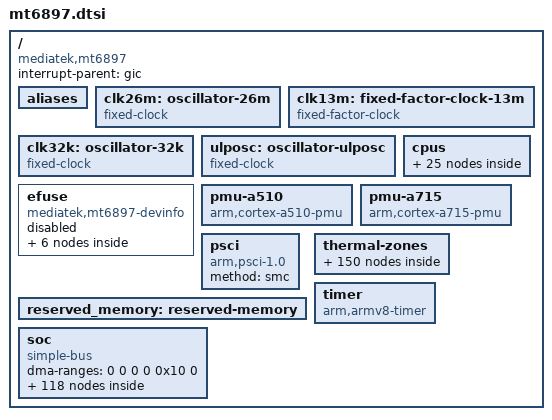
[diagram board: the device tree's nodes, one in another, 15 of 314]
// SPDX-License-Identifier: (GPL-2.0-only OR BSD-2-Clause)
/*
 * MediaTek MT6897 (Dimensity 8300, sold as MT8792 in tablets) SoC
 *
 * Copyright (c) 2026 buntOS contributors
 *
 * Register and interrupt values come from the SoC device tree in the
 * Lenovo TB373FU/TB375FC stock firmware and were checked against the
 * MediaTek downstream mt6897.dts and the community port
 * https://github.com/u0n0u/tb375fc-linux. Blocks that need the missing
 * clock, pinctrl and power domain drivers are described but disabled.
 */

#include <dt-bindings/thermal/thermal.h>
#include <dt-bindings/clock/mediatek,mt6897-clock.h>
#include <dt-bindings/interrupt-controller/arm-gic.h>
#include <dt-bindings/interrupt-controller/irq.h>
#include <dt-bindings/memory/mediatek,mt6897-memory-port.h>
#include <dt-bindings/phy/phy.h>
#include <dt-bindings/power/mediatek,mt6897-power.h>
#include <dt-bindings/reset/mediatek,mt6897-resets.h>
#include <dt-bindings/thermal/mediatek,lvts-thermal.h>

/ {
	compatible = "mediatek,mt6897";
	interrupt-parent = <&gic>;
	#address-cells = <2>;
	#size-cells = <2>;

	/*
	 * mediatek-drm finds the blocks of the display by these. The numbers of
	 * the display controllers are in mt6897_main_controllers of mtk_drm_drv.c.
	 */
	aliases {
		dsc0 = &dsc0;
		dsc1 = &dsc1;
		dsi0 = &dsi0;
		dsi1 = &dsi1;
		mmsys0 = &dispsys0;
		mmsys1 = &dispsys1;
		mmsys2 = &ovlsys0;
		mmsys3 = &ovlsys1;
		mutex0 = &disp_mutex0;
		mutex1 = &disp_mutex1;
		mutex2 = &ovl_mutex0;
		mutex3 = &ovl_mutex1;
		ovl-2l0 = &ovl_2l0;
		ovl-2l1 = &ovl_2l1;
	};

	clk26m: oscillator-26m {
		compatible = "fixed-clock";
		#clock-cells = <0>;
		clock-frequency = <26000000>;
		clock-output-names = "clk26m";
	};

	clk13m: fixed-factor-clock-13m {
		compatible = "fixed-factor-clock";
		#clock-cells = <0>;
		clocks = <&clk26m>;
		clock-div = <2>;
		clock-mult = <1>;
		clock-output-names = "clk13m";
	};

	/* The stock firmware gives 32000 Hz, not 32768 */
	clk32k: oscillator-32k {
		compatible = "fixed-clock";
		#clock-cells = <0>;
		clock-frequency = <32000>;
		clock-output-names = "clk32k";
	};

	/* On-chip ultra low power oscillator, the osc_dN dividers' parent */
	ulposc: oscillator-ulposc {
		compatible = "fixed-clock";
		#clock-cells = <0>;
		clock-frequency = <588000000>;
		clock-output-names = "ulposc";
	};

	cpus {
		#address-cells = <1>;
		#size-cells = <0>;

		cpu0: cpu@0 {
			device_type = "cpu";
			compatible = "arm,cortex-a510";
			reg = <0x000>;
			enable-method = "psci";
			performance-domains = <&performance 0>;
			capacity-dmips-mhz = <338>;
			#cooling-cells = <2>;
			cpu-idle-states = <&cpu_off_l &cluster_off_l>;
		};

		cpu1: cpu@100 {
			device_type = "cpu";
			compatible = "arm,cortex-a510";
			reg = <0x100>;
			enable-method = "psci";
			performance-domains = <&performance 0>;
			capacity-dmips-mhz = <338>;
			#cooling-cells = <2>;
			cpu-idle-states = <&cpu_off_l &cluster_off_l>;
		};

		cpu2: cpu@200 {
			device_type = "cpu";
			compatible = "arm,cortex-a510";
			reg = <0x200>;
			enable-method = "psci";
			performance-domains = <&performance 0>;
			capacity-dmips-mhz = <338>;
			#cooling-cells = <2>;
			cpu-idle-states = <&cpu_off_l &cluster_off_l>;
		};

		cpu3: cpu@300 {
			device_type = "cpu";
			compatible = "arm,cortex-a510";
			reg = <0x300>;
			enable-method = "psci";
			performance-domains = <&performance 0>;
			capacity-dmips-mhz = <338>;
			#cooling-cells = <2>;
			cpu-idle-states = <&cpu_off_l &cluster_off_l>;
		};

		cpu4: cpu@400 {
			device_type = "cpu";
			compatible = "arm,cortex-a715";
			reg = <0x400>;
			enable-method = "psci";
			performance-domains = <&performance 1>;
			capacity-dmips-mhz = <1080>;
			#cooling-cells = <2>;
			cpu-idle-states = <&cpu_off_m &cluster_off_m>;
		};

		cpu5: cpu@500 {
			device_type = "cpu";
			compatible = "arm,cortex-a715";
			reg = <0x500>;
			enable-method = "psci";
			performance-domains = <&performance 1>;
			capacity-dmips-mhz = <1080>;
			#cooling-cells = <2>;
			cpu-idle-states = <&cpu_off_m &cluster_off_m>;
		};

		cpu6: cpu@600 {
			device_type = "cpu";
			compatible = "arm,cortex-a715";
			reg = <0x600>;
			enable-method = "psci";
			performance-domains = <&performance 1>;
			capacity-dmips-mhz = <1080>;
			#cooling-cells = <2>;
			cpu-idle-states = <&cpu_off_m &cluster_off_m>;
		};

		cpu7: cpu@700 {
			device_type = "cpu";
			compatible = "arm,cortex-a715";
			reg = <0x700>;
			enable-method = "psci";
			performance-domains = <&performance 2>;
			capacity-dmips-mhz = <1024>;
			#cooling-cells = <2>;
			cpu-idle-states = <&cpu_off_b &cluster_off_b>;
		};

		/* One DynamIQ cluster; the three DVFS domains are performance-domains */
		cpu-map {
			cluster0 {
				core0 {
					cpu = <&cpu0>;
				};

				core1 {
					cpu = <&cpu1>;
				};

				core2 {
					cpu = <&cpu2>;
				};

				core3 {
					cpu = <&cpu3>;
				};

				core4 {
					cpu = <&cpu4>;
				};

				core5 {
					cpu = <&cpu5>;
				};

				core6 {
					cpu = <&cpu6>;
				};

				core7 {
					cpu = <&cpu7>;
				};
			};
		};

		/*
		 * Only the CPU and cluster power-down states. The deeper MCUSYS
		 * and system states are coordinated by the SPM and need its
		 * driver first.
		 */
		idle-states {
			entry-method = "psci";

			cpu_off_l: cpu-off-l {
				compatible = "arm,idle-state";
				arm,psci-suspend-param = <0x00010000>;
				local-timer-stop;
				entry-latency-us = <126>;
				exit-latency-us = <251>;
				min-residency-us = <5700>;
			};

			cpu_off_m: cpu-off-m {
				compatible = "arm,idle-state";
				arm,psci-suspend-param = <0x00010000>;
				local-timer-stop;
				entry-latency-us = <77>;
				exit-latency-us = <179>;
				min-residency-us = <2520>;
			};

			cpu_off_b: cpu-off-b {
				compatible = "arm,idle-state";
				arm,psci-suspend-param = <0x00010000>;
				local-timer-stop;
				entry-latency-us = <52>;
				exit-latency-us = <129>;
				min-residency-us = <1890>;
			};

			cluster_off_l: cluster-off-l {
				compatible = "arm,idle-state";
				arm,psci-suspend-param = <0x01010001>;
				local-timer-stop;
				entry-latency-us = <143>;
				exit-latency-us = <420>;
				min-residency-us = <5700>;
			};

			cluster_off_m: cluster-off-m {
				compatible = "arm,idle-state";
				arm,psci-suspend-param = <0x01010001>;
				local-timer-stop;
				entry-latency-us = <82>;
				exit-latency-us = <253>;
				min-residency-us = <3020>;
			};

			cluster_off_b: cluster-off-b {
				compatible = "arm,idle-state";
				arm,psci-suspend-param = <0x01010001>;
				local-timer-stop;
				entry-latency-us = <46>;
				exit-latency-us = <150>;
				min-residency-us = <2460>;
			};
		};
	};

	/*
	 * The fuses as the boot firmware passes them on. The cell offsets are in
	 * that copy (atag,devinfo), not in the efuse block at 0x11e80000.
	 */
	efuse: efuse {
		compatible = "mediatek,mt6897-devinfo";
		status = "disabled";

		nvmem-layout {
			compatible = "fixed-layout";
			#address-cells = <1>;
			#size-cells = <1>;

			/* Termination trims of CSI port 0, for the seninf */
			csi_trim0: csi-trim@1d4 {
				reg = <0x1d4 0x4>;
			};

			lvts_calib2: calib@2d4 {
				reg = <0x2d4 0x28>;
			};

			lvts_calib4: calib@2fc {
				reg = <0x2fc 0x10>;
			};

			lvts_calib1: calib@310 {
				reg = <0x310 0x38>;
			};

			lvts_calib3: calib@364 {
				reg = <0x364 0x4>;
			};
		};
	};

	pmu-a510 {
		compatible = "arm,cortex-a510-pmu";
		interrupt-parent = <&gic>;
		interrupts = <GIC_PPI 7 IRQ_TYPE_LEVEL_HIGH &ppi_cluster0>;
	};

	pmu-a715 {
		compatible = "arm,cortex-a715-pmu";
		interrupt-parent = <&gic>;
		interrupts = <GIC_PPI 7 IRQ_TYPE_LEVEL_HIGH &ppi_cluster1>;
	};

	psci {
		compatible = "arm,psci-1.0";
		method = "smc";
	};

	/*
	 * The bootloader adds its fixed carve-outs (ATF, TEE, GenieZone,
	 * connsys, framebuffer, ...) here at boot.
	 */
	reserved_memory: reserved-memory {
		#address-cells = <2>;
		#size-cells = <2>;
		ranges;
	};

	thermal-zones {
		cpu4-0-thermal {
			polling-delay = <1000>;
			polling-delay-passive = <150>;
			thermal-sensors = <&lvts_mcu MT6897_MCU_MEDIUM_CPU4_0>;

			trips {
				cpu4_0_alert: trip-alert {
					temperature = <85000>;
					hysteresis = <2000>;
					type = "passive";
				};

				trip-crit {
					temperature = <115000>;
					hysteresis = <2000>;
					type = "critical";
				};
			};

			cooling-maps {
				map0 {
					trip = <&cpu4_0_alert>;
					cooling-device = <&cpu4 THERMAL_NO_LIMIT THERMAL_NO_LIMIT>;
				};
			};
		};

		cpu4-1-thermal {
			polling-delay = <1000>;
			polling-delay-passive = <150>;
			thermal-sensors = <&lvts_mcu MT6897_MCU_MEDIUM_CPU4_1>;

			trips {
				cpu4_1_alert: trip-alert {
					temperature = <85000>;
					hysteresis = <2000>;
					type = "passive";
				};

				trip-crit {
					temperature = <115000>;
					hysteresis = <2000>;
					type = "critical";
				};
			};

			cooling-maps {
				map0 {
					trip = <&cpu4_1_alert>;
					cooling-device = <&cpu4 THERMAL_NO_LIMIT THERMAL_NO_LIMIT>;
				};
			};
		};

		cpu5-0-thermal {
			polling-delay = <1000>;
			polling-delay-passive = <150>;
			thermal-sensors = <&lvts_mcu MT6897_MCU_MEDIUM_CPU5_0>;

			trips {
				cpu5_0_alert: trip-alert {
					temperature = <85000>;
					hysteresis = <2000>;
					type = "passive";
				};

				trip-crit {
					temperature = <115000>;
					hysteresis = <2000>;
					type = "critical";
				};
			};

			cooling-maps {
				map0 {
					trip = <&cpu5_0_alert>;
					cooling-device = <&cpu4 THERMAL_NO_LIMIT THERMAL_NO_LIMIT>;
				};
			};
		};

		cpu5-1-thermal {
			polling-delay = <1000>;
			polling-delay-passive = <150>;
			thermal-sensors = <&lvts_mcu MT6897_MCU_MEDIUM_CPU5_1>;

			trips {
				cpu5_1_alert: trip-alert {
					temperature = <85000>;
					hysteresis = <2000>;
					type = "passive";
				};

				trip-crit {
					temperature = <115000>;
					hysteresis = <2000>;
					type = "critical";
				};
			};

			cooling-maps {
				map0 {
					trip = <&cpu5_1_alert>;
					cooling-device = <&cpu4 THERMAL_NO_LIMIT THERMAL_NO_LIMIT>;
				};
			};
		};

		cpu2-thermal {
			polling-delay = <1000>;
			polling-delay-passive = <150>;
			thermal-sensors = <&lvts_mcu MT6897_MCU_LITTLE_CPU2>;

			trips {
				cpu2_alert: trip-alert {
					temperature = <85000>;
					hysteresis = <2000>;
					type = "passive";
				};

				trip-crit {
					temperature = <115000>;
					hysteresis = <2000>;
					type = "critical";
				};
			};

			cooling-maps {
				map0 {
					trip = <&cpu2_alert>;
					cooling-device = <&cpu0 THERMAL_NO_LIMIT THERMAL_NO_LIMIT>;
				};
			};
		};

		cpu3-thermal {
			polling-delay = <1000>;
			polling-delay-passive = <150>;
			thermal-sensors = <&lvts_mcu MT6897_MCU_LITTLE_CPU3>;

			trips {
				cpu3_alert: trip-alert {
					temperature = <85000>;
					hysteresis = <2000>;
					type = "passive";
				};

				trip-crit {
					temperature = <115000>;
					hysteresis = <2000>;
					type = "critical";
				};
			};

			cooling-maps {
				map0 {
					trip = <&cpu3_alert>;
					cooling-device = <&cpu0 THERMAL_NO_LIMIT THERMAL_NO_LIMIT>;
				};
			};
		};

		cpu6-0-thermal {
			polling-delay = <1000>;
			polling-delay-passive = <150>;
			thermal-sensors = <&lvts_mcu MT6897_MCU_MEDIUM_CPU6_0>;

			trips {
				cpu6_0_alert: trip-alert {
					temperature = <85000>;
					hysteresis = <2000>;
					type = "passive";
				};

				trip-crit {
					temperature = <115000>;
					hysteresis = <2000>;
					type = "critical";
				};
			};

			cooling-maps {
				map0 {
					trip = <&cpu6_0_alert>;
					cooling-device = <&cpu4 THERMAL_NO_LIMIT THERMAL_NO_LIMIT>;
				};
			};
		};

		cpu6-1-thermal {
			polling-delay = <1000>;
			polling-delay-passive = <150>;
			thermal-sensors = <&lvts_mcu MT6897_MCU_MEDIUM_CPU6_1>;

			trips {
				cpu6_1_alert: trip-alert {
					temperature = <85000>;
					hysteresis = <2000>;
					type = "passive";
				};

				trip-crit {
					temperature = <115000>;
					hysteresis = <2000>;
					type = "critical";
				};
			};

			cooling-maps {
				map0 {
					trip = <&cpu6_1_alert>;
					cooling-device = <&cpu4 THERMAL_NO_LIMIT THERMAL_NO_LIMIT>;
				};
			};
		};

		dsu0-thermal {
			polling-delay = <1000>;
			polling-delay-passive = <150>;
			thermal-sensors = <&lvts_mcu MT6897_MCU_DSU0>;

			trips {
				dsu0_alert: trip-alert {
					temperature = <85000>;
					hysteresis = <2000>;
					type = "passive";
				};

				trip-crit {
					temperature = <115000>;
					hysteresis = <2000>;
					type = "critical";
				};
			};

			cooling-maps {
				map0 {
					trip = <&dsu0_alert>;
					cooling-device = <&cpu0 THERMAL_NO_LIMIT THERMAL_NO_LIMIT>,
							 <&cpu4 THERMAL_NO_LIMIT THERMAL_NO_LIMIT>,
							 <&cpu7 THERMAL_NO_LIMIT THERMAL_NO_LIMIT>;
				};
			};
		};

		cpu0-thermal {
			polling-delay = <1000>;
			polling-delay-passive = <150>;
			thermal-sensors = <&lvts_mcu MT6897_MCU_LITTLE_CPU0>;

			trips {
				cpu0_alert: trip-alert {
					temperature = <85000>;
					hysteresis = <2000>;
					type = "passive";
				};

				trip-crit {
					temperature = <115000>;
					hysteresis = <2000>;
					type = "critical";
				};
			};

			cooling-maps {
				map0 {
					trip = <&cpu0_alert>;
					cooling-device = <&cpu0 THERMAL_NO_LIMIT THERMAL_NO_LIMIT>;
				};
			};
		};

		cpu1-thermal {
			polling-delay = <1000>;
			polling-delay-passive = <150>;
			thermal-sensors = <&lvts_mcu MT6897_MCU_LITTLE_CPU1>;

			trips {
				cpu1_alert: trip-alert {
					temperature = <85000>;
					hysteresis = <2000>;
					type = "passive";
				};

				trip-crit {
					temperature = <115000>;
					hysteresis = <2000>;
					type = "critical";
				};
			};

			cooling-maps {
				map0 {
					trip = <&cpu1_alert>;
					cooling-device = <&cpu0 THERMAL_NO_LIMIT THERMAL_NO_LIMIT>;
				};
			};
		};

		dsu1-thermal {
			polling-delay = <1000>;
			polling-delay-passive = <150>;
			thermal-sensors = <&lvts_mcu MT6897_MCU_DSU1>;

			trips {
				dsu1_alert: trip-alert {
					temperature = <85000>;
					hysteresis = <2000>;
					type = "passive";
				};

				trip-crit {
					temperature = <115000>;
					hysteresis = <2000>;
					type = "critical";
				};
			};

			cooling-maps {
				map0 {
					trip = <&dsu1_alert>;
					cooling-device = <&cpu0 THERMAL_NO_LIMIT THERMAL_NO_LIMIT>,
							 <&cpu4 THERMAL_NO_LIMIT THERMAL_NO_LIMIT>,
							 <&cpu7 THERMAL_NO_LIMIT THERMAL_NO_LIMIT>;
				};
			};
		};

		cpu7-0-thermal {
			polling-delay = <1000>;
			polling-delay-passive = <150>;
			thermal-sensors = <&lvts_mcu MT6897_MCU_BIG_CPU7_0>;

			trips {
				cpu7_0_alert: trip-alert {
					temperature = <85000>;
					hysteresis = <2000>;
					type = "passive";
				};

				trip-crit {
					temperature = <115000>;
					hysteresis = <2000>;
					type = "critical";
				};
			};

			cooling-maps {
				map0 {
					trip = <&cpu7_0_alert>;
					cooling-device = <&cpu7 THERMAL_NO_LIMIT THERMAL_NO_LIMIT>;
				};
			};
		};

		cpu7-1-thermal {
			polling-delay = <1000>;
			polling-delay-passive = <150>;
			thermal-sensors = <&lvts_mcu MT6897_MCU_BIG_CPU7_1>;

			trips {
				cpu7_1_alert: trip-alert {
					temperature = <85000>;
					hysteresis = <2000>;
					type = "passive";
				};

				trip-crit {
					temperature = <115000>;
					hysteresis = <2000>;
					type = "critical";
				};
			};

			cooling-maps {
				map0 {
					trip = <&cpu7_1_alert>;
					cooling-device = <&cpu7 THERMAL_NO_LIMIT THERMAL_NO_LIMIT>;
				};
			};
		};

		dsu2-thermal {
			polling-delay = <1000>;
			polling-delay-passive = <150>;
			thermal-sensors = <&lvts_mcu MT6897_MCU_DSU2>;

			trips {
				dsu2_alert: trip-alert {
					temperature = <85000>;
					hysteresis = <2000>;
					type = "passive";
				};

				trip-crit {
					temperature = <115000>;
					hysteresis = <2000>;
					type = "critical";
				};
			};

			cooling-maps {
				map0 {
					trip = <&dsu2_alert>;
					cooling-device = <&cpu0 THERMAL_NO_LIMIT THERMAL_NO_LIMIT>,
							 <&cpu4 THERMAL_NO_LIMIT THERMAL_NO_LIMIT>,
							 <&cpu7 THERMAL_NO_LIMIT THERMAL_NO_LIMIT>;
				};
			};
		};

		dsu3-thermal {
			polling-delay = <1000>;
			polling-delay-passive = <150>;
			thermal-sensors = <&lvts_mcu MT6897_MCU_DSU3>;

			trips {
				dsu3_alert: trip-alert {
					temperature = <85000>;
					hysteresis = <2000>;
					type = "passive";
				};

				trip-crit {
					temperature = <115000>;
					hysteresis = <2000>;
					type = "critical";
				};
			};

			cooling-maps {
				map0 {
					trip = <&dsu3_alert>;
					cooling-device = <&cpu0 THERMAL_NO_LIMIT THERMAL_NO_LIMIT>,
							 <&cpu4 THERMAL_NO_LIMIT THERMAL_NO_LIMIT>,
							 <&cpu7 THERMAL_NO_LIMIT THERMAL_NO_LIMIT>;
				};
			};
		};

		soc-top0-thermal {
			polling-delay = <1000>;
			thermal-sensors = <&lvts_ap MT6897_AP_TOP0>;

			trips {
				trip-crit {
					temperature = <115000>;
					hysteresis = <2000>;
					type = "critical";
				};
			};
		};

		soc-top1-thermal {
			polling-delay = <1000>;
			thermal-sensors = <&lvts_ap MT6897_AP_TOP1>;

			trips {
				trip-crit {
					temperature = <115000>;
					hysteresis = <2000>;
					type = "critical";
				};
			};
		};

		soc-top2-thermal {
			polling-delay = <1000>;
			thermal-sensors = <&lvts_ap MT6897_AP_TOP2>;

			trips {
				trip-crit {
					temperature = <115000>;
					hysteresis = <2000>;
					type = "critical";
				};
			};
		};

		soc-top3-thermal {
			polling-delay = <1000>;
			thermal-sensors = <&lvts_ap MT6897_AP_TOP3>;

			trips {
				trip-crit {
					temperature = <115000>;
					hysteresis = <2000>;
					type = "critical";
				};
			};
		};

		soc-bot0-thermal {
			polling-delay = <1000>;
			thermal-sensors = <&lvts_ap MT6897_AP_BOT0>;

			trips {
				trip-crit {
					temperature = <115000>;
					hysteresis = <2000>;
					type = "critical";
				};
			};
		};

		soc-bot1-thermal {
			polling-delay = <1000>;
			thermal-sensors = <&lvts_ap MT6897_AP_BOT1>;

			trips {
				trip-crit {
					temperature = <115000>;
					hysteresis = <2000>;
					type = "critical";
				};
			};
		};

		soc-bot2-thermal {
			polling-delay = <1000>;
			thermal-sensors = <&lvts_ap MT6897_AP_BOT2>;

			trips {
				trip-crit {
					temperature = <115000>;
					hysteresis = <2000>;
					type = "critical";
				};
			};
		};

		soc-bot3-thermal {
			polling-delay = <1000>;
			thermal-sensors = <&lvts_ap MT6897_AP_BOT3>;

			trips {
				trip-crit {
					temperature = <115000>;
					hysteresis = <2000>;
					type = "critical";
				};
			};
		};

		md0-thermal {
			polling-delay = <1000>;
			thermal-sensors = <&lvts_ap MT6897_AP_MD0>;

			trips {
				trip-crit {
					temperature = <115000>;
					hysteresis = <2000>;
					type = "critical";
				};
			};
		};

		md1-thermal {
			polling-delay = <1000>;
			thermal-sensors = <&lvts_ap MT6897_AP_MD1>;

			trips {
				trip-crit {
					temperature = <115000>;
					hysteresis = <2000>;
					type = "critical";
				};
			};
		};

		md2-thermal {
			polling-delay = <1000>;
			thermal-sensors = <&lvts_ap MT6897_AP_MD2>;

			trips {
				trip-crit {
					temperature = <115000>;
					hysteresis = <2000>;
					type = "critical";
				};
			};
		};

		md3-thermal {
			polling-delay = <1000>;
			thermal-sensors = <&lvts_ap MT6897_AP_MD3>;

			trips {
				trip-crit {
					temperature = <115000>;
					hysteresis = <2000>;
					type = "critical";
				};
			};
		};

		apu0-thermal {
			polling-delay = <1000>;
			thermal-sensors = <&lvts_apu MT6897_APU0>;

			trips {
				trip-crit {
					temperature = <115000>;
					hysteresis = <2000>;
					type = "critical";
				};
			};
		};

		apu1-thermal {
			polling-delay = <1000>;
			thermal-sensors = <&lvts_apu MT6897_APU1>;

			trips {
				trip-crit {
					temperature = <115000>;
					hysteresis = <2000>;
					type = "critical";
				};
			};
		};

		gpu0-thermal {
			polling-delay = <1000>;
			polling-delay-passive = <150>;
			thermal-sensors = <&lvts_gpu MT6897_GPU0>;

			trips {
				gpu0_alert: trip-alert {
					temperature = <85000>;
					hysteresis = <2000>;
					type = "passive";
				};

				trip-crit {
					temperature = <115000>;
					hysteresis = <2000>;
					type = "critical";
				};
			};

			cooling-maps {
				map0 {
					trip = <&gpu0_alert>;
					cooling-device = <&gpu THERMAL_NO_LIMIT THERMAL_NO_LIMIT>;
				};
			};
		};

		gpu1-thermal {
			polling-delay = <1000>;
			polling-delay-passive = <150>;
			thermal-sensors = <&lvts_gpu MT6897_GPU1>;

			trips {
				gpu1_alert: trip-alert {
					temperature = <85000>;
					hysteresis = <2000>;
					type = "passive";
				};

				trip-crit {
					temperature = <115000>;
					hysteresis = <2000>;
					type = "critical";
				};
			};

			cooling-maps {
				map0 {
					trip = <&gpu1_alert>;
					cooling-device = <&gpu THERMAL_NO_LIMIT THERMAL_NO_LIMIT>;
				};
			};
		};
	};

	timer: timer {
		compatible = "arm,armv8-timer";
		interrupt-parent = <&gic>;
		interrupts = <GIC_PPI 13 IRQ_TYPE_LEVEL_HIGH 0>,
			     <GIC_PPI 14 IRQ_TYPE_LEVEL_HIGH 0>,
			     <GIC_PPI 11 IRQ_TYPE_LEVEL_HIGH 0>,
			     <GIC_PPI 10 IRQ_TYPE_LEVEL_HIGH 0>;
		clock-frequency = <13000000>;
	};

	soc {
		compatible = "simple-bus";
		#address-cells = <2>;
		#size-cells = <2>;
		ranges;
		dma-ranges = <0 0 0 0 0x10 0>;

		/* CPU DVFS in the MCUPM, one register bank per frequency domain */
		performance: performance-controller@11bc10 {
			compatible = "mediatek,cpufreq-hw";
			reg = <0 0x0011bc10 0 0x120>,
			      <0 0x0011bd30 0 0x120>,
			      <0 0x0011be50 0 0x120>;
			#performance-domain-cells = <1>;
		};

		/* Needed before the firmware accepts PSCI CPU_SUSPEND */
		mcupm@c0bf600 {
			compatible = "mediatek,mt6897-mcupm";
			reg = <0 0x0c0bf600 0 0xa00>;
		};

		/*
		 * Unlike MT8183..MT8195 the GIC is not at 0x0c000000: that
		 * range is MCUSYS (mcucfg, CPU PLLs, MCUPM at 0x0c070000).
		 * Both the shipped SoC tree and the tree the bootloader hands
		 * to the kernel use this base, as does the community port.
		 */
		gic: interrupt-controller@c400000 {
			compatible = "arm,gic-v3";
			#interrupt-cells = <4>;
			#redistributor-regions = <1>;
			interrupt-parent = <&gic>;
			interrupt-controller;
			reg = <0 0x0c400000 0 0x40000>,
			      <0 0x0c440000 0 0x200000>;
			interrupts = <GIC_PPI 9 IRQ_TYPE_LEVEL_HIGH 0>;

			ppi-partitions {
				ppi_cluster0: interrupt-partition-0 {
					affinity = <&cpu0 &cpu1 &cpu2 &cpu3>;
				};

				ppi_cluster1: interrupt-partition-1 {
					affinity = <&cpu4 &cpu5 &cpu6 &cpu7>;
				};
			};
		};

		/*
		 * The clock controllers stay off in 2a, which runs on the clocks
		 * the bootloader left on. TODO(2b): enable all six together with
		 * pio and SPMI, keeping clk_ignore_unused on the command line.
		 */
		topckgen: clock-controller@10000000 {
			compatible = "mediatek,mt6897-topckgen", "syscon";
			reg = <0 0x10000000 0 0x1000>;
			mediatek,hardware-voter = <&hwv>;
			#clock-cells = <1>;
			status = "disabled";
		};

		/*
		 * 232 GPIOs and the five EINT blocks. EINTs 232-249 have no
		 * pin; the driver gives them virtual GPIOs (the SPMI rcs
		 * interrupt is EINT 248). TODO(2b): enable together with SPMI.
		 */
		pio: pinctrl@10005000 {
			compatible = "mediatek,mt6897-pinctrl";
			reg = <0 0x10005000 0 0x1000>,
			      <0 0x11b20000 0 0x1000>,
			      <0 0x11c00000 0 0x1000>,
			      <0 0x11d30000 0 0x1000>,
			      <0 0x11d40000 0 0x1000>,
			      <0 0x11d50000 0 0x1000>,
			      <0 0x11ea0000 0 0x1000>,
			      <0 0x11eb0000 0 0x1000>,
			      <0 0x11f20000 0 0x1000>,
			      <0 0x11f30000 0 0x1000>,
			      <0 0x11ce0000 0 0x1000>,
			      <0 0x11de0000 0 0x1000>,
			      <0 0x11e90000 0 0x1000>,
			      <0 0x11fe0000 0 0x1000>,
			      <0 0x1c01e000 0 0x1000>;
			reg-names = "base", "rt", "rm", "bl", "bm", "br",
				    "lb", "lt", "tm", "tl", "eint-e", "eint-s",
				    "eint-w", "eint-n", "eint-c";
			gpio-controller;
			#gpio-cells = <2>;
			gpio-ranges = <&pio 0 0 232>;
			interrupt-controller;
			interrupts = <GIC_SPI 309 IRQ_TYPE_LEVEL_HIGH 0>;
			#interrupt-cells = <2>;
			status = "disabled";
		};

		apmixedsys: clock-controller@1000c000 {
			compatible = "mediatek,mt6897-apmixedsys", "syscon";
			reg = <0 0x1000c000 0 0x1000>;
			mediatek,hardware-voter = <&hwv>;
			#clock-cells = <1>;
			status = "disabled";
		};

		/*
		 * Bus protection registers of the power domains, which take them
		 * as a regmap. They stay disabled: nothing binds to a plain
		 * syscon, and fw_devlink would make the power controller wait
		 * for it through access-controllers until the deferred probe
		 * timeout.
		 */
		ifr_bus: syscon@1002c000 {
			compatible = "mediatek,mt6897-ifr-bus", "syscon";
			reg = <0 0x1002c000 0 0x1000>;
			status = "disabled";
		};

		/*
		 * Hardware voter: collects the clock votes of the AP and the
		 * remote processors, and switches some PLLs, muxes and gates,
		 * and some of the power domains.
		 */
		lvts_ap: thermal-sensor@10315000 {
			compatible = "mediatek,mt6897-lvts-ap";
			reg = <0 0x10315000 0 0x1000>;
			interrupts = <GIC_SPI 264 IRQ_TYPE_LEVEL_HIGH 0>;
			nvmem-cells = <&lvts_calib1>, <&lvts_calib2>,
				      <&lvts_calib3>, <&lvts_calib4>;
			nvmem-cell-names = "lvts-calib-data-1", "lvts-calib-data-2",
					   "lvts-calib-data-3", "lvts-calib-data-4";
			#thermal-sensor-cells = <1>;
			status = "disabled";
		};

		lvts_mcu: thermal-sensor@10316000 {
			compatible = "mediatek,mt6897-lvts-mcu";
			reg = <0 0x10316000 0 0x1000>;
			interrupts = <GIC_SPI 265 IRQ_TYPE_LEVEL_HIGH 0>;
			nvmem-cells = <&lvts_calib1>, <&lvts_calib2>,
				      <&lvts_calib3>, <&lvts_calib4>;
			nvmem-cell-names = "lvts-calib-data-1", "lvts-calib-data-2",
					   "lvts-calib-data-3", "lvts-calib-data-4";
			#thermal-sensor-cells = <1>;
			status = "disabled";
		};

		hwv: syscon@10320000 {
			compatible = "mediatek,mt6897-hwv", "syscon";
			reg = <0 0x10320000 0 0x2000>;
		};

		/*
		 * 8250_mtk needs a "bus" clock next to "baud". uart0 is the 2a
		 * console, so it keeps clk26m there and does not wait for the
		 * clock controllers. TODO(2b): <&pericfg_ao CLK_PERI_AO_UART0>.
		 */
		uart0: serial@11001000 {
			compatible = "mediatek,mt6897-uart", "mediatek,mt6577-uart";
			reg = <0 0x11001000 0 0x1000>;
			interrupts = <GIC_SPI 250 IRQ_TYPE_LEVEL_HIGH 0>;
			clocks = <&clk26m>, <&clk26m>;
			clock-names = "baud", "bus";
			status = "disabled";
		};

		uart1: serial@11002000 {
			compatible = "mediatek,mt6897-uart", "mediatek,mt6577-uart";
			reg = <0 0x11002000 0 0x1000>;
			interrupts = <GIC_SPI 251 IRQ_TYPE_LEVEL_HIGH 0>;
			clocks = <&clk26m>, <&pericfg_ao CLK_PERI_AO_UART1>;
			clock-names = "baud", "bus";
			status = "disabled";
		};

		uart2: serial@11003000 {
			compatible = "mediatek,mt6897-uart", "mediatek,mt6577-uart";
			reg = <0 0x11003000 0 0x1000>;
			interrupts = <GIC_SPI 252 IRQ_TYPE_LEVEL_HIGH 0>;
			clocks = <&clk26m>, <&pericfg_ao CLK_PERI_AO_UART2>;
			clock-names = "baud", "bus";
			status = "disabled";
		};

		/*
		 * UART3 reaches its pads or the UART hub, which this SoC has
		 * but MT6897 boards do not use (stock uarthub-disable).
		 */
		uart3: serial@11004000 {
			compatible = "mediatek,mt6897-uart", "mediatek,mt6577-uart";
			reg = <0 0x11004000 0 0x1000>;
			interrupts = <GIC_SPI 253 IRQ_TYPE_LEVEL_HIGH 0>;
			clocks = <&clk26m>, <&pericfg_ao CLK_PERI_AO_UART3>;
			clock-names = "baud", "bus";
			mediatek,syscon-pad-mode = <&pericfg_ao 0x50>;
			status = "disabled";
		};

		disp_pwm0: pwm@1100e000 {
			compatible = "mediatek,mt6897-disp-pwm", "mediatek,mt8183-disp-pwm";
			reg = <0 0x1100e000 0 0x1000>;
			interrupts = <GIC_SPI 254 IRQ_TYPE_LEVEL_HIGH 0>;
			clocks = <&topckgen CLK_TOP_DISP_PWM>,
				 <&pericfg_ao CLK_PERI_AO_DISP_PWM0>;
			clock-names = "main", "mm";
			#pwm-cells = <2>;
			status = "disabled";
		};

		/*
		 * The SPI masters take their clock from a topckgen mux behind a
		 * pericfg_ao gate. As in the stock tree, spi0-2 run from
		 * mainpll_d6_d2 and spi3-7 from univpll_d6_d2. The stock
		 * mediatek,tickdly sample delays have no mainline property.
		 * TODO(2c): enable with pio and the clock controllers.
		 */
		spi0: spi@11010000 {
			compatible = "mediatek,mt6897-spi", "mediatek,mt6991-spi";
			reg = <0 0x11010000 0 0x100>;
			interrupts = <GIC_SPI 242 IRQ_TYPE_LEVEL_HIGH 0>;
			clocks = <&topckgen CLK_TOP_MAINPLL_D6_D2>,
				 <&topckgen CLK_TOP_SPI0>,
				 <&pericfg_ao CLK_PERI_AO_SPI0_BCLK>;
			clock-names = "parent-clk", "sel-clk", "spi-clk";
			mediatek,pad-select = <0>;
			#address-cells = <1>;
			#size-cells = <0>;
			status = "disabled";
		};

		spi1: spi@11011000 {
			compatible = "mediatek,mt6897-spi", "mediatek,mt6991-spi";
			reg = <0 0x11011000 0 0x100>;
			interrupts = <GIC_SPI 243 IRQ_TYPE_LEVEL_HIGH 0>;
			clocks = <&topckgen CLK_TOP_MAINPLL_D6_D2>,
				 <&topckgen CLK_TOP_SPI1>,
				 <&pericfg_ao CLK_PERI_AO_SPI1_BCLK>;
			clock-names = "parent-clk", "sel-clk", "spi-clk";
			mediatek,pad-select = <0>;
			#address-cells = <1>;
			#size-cells = <0>;
			status = "disabled";
		};

		spi2: spi@11012000 {
			compatible = "mediatek,mt6897-spi", "mediatek,mt6991-spi";
			reg = <0 0x11012000 0 0x100>;
			interrupts = <GIC_SPI 244 IRQ_TYPE_LEVEL_HIGH 0>;
			clocks = <&topckgen CLK_TOP_MAINPLL_D6_D2>,
				 <&topckgen CLK_TOP_SPI2>,
				 <&pericfg_ao CLK_PERI_AO_SPI2_BCLK>;
			clock-names = "parent-clk", "sel-clk", "spi-clk";
			mediatek,pad-select = <0>;
			#address-cells = <1>;
			#size-cells = <0>;
			status = "disabled";
		};

		spi3: spi@11013000 {
			compatible = "mediatek,mt6897-spi", "mediatek,mt6991-spi";
			reg = <0 0x11013000 0 0x100>;
			interrupts = <GIC_SPI 245 IRQ_TYPE_LEVEL_HIGH 0>;
			clocks = <&topckgen CLK_TOP_UNIVPLL_D6_D2>,
				 <&topckgen CLK_TOP_SPI3>,
				 <&pericfg_ao CLK_PERI_AO_SPI3_BCLK>;
			clock-names = "parent-clk", "sel-clk", "spi-clk";
			mediatek,pad-select = <0>;
			#address-cells = <1>;
			#size-cells = <0>;
			status = "disabled";
		};

		spi4: spi@11014000 {
			compatible = "mediatek,mt6897-spi", "mediatek,mt6991-spi";
			reg = <0 0x11014000 0 0x100>;
			interrupts = <GIC_SPI 246 IRQ_TYPE_LEVEL_HIGH 0>;
			clocks = <&topckgen CLK_TOP_UNIVPLL_D6_D2>,
				 <&topckgen CLK_TOP_SPI4>,
				 <&pericfg_ao CLK_PERI_AO_SPI4_BCLK>;
			clock-names = "parent-clk", "sel-clk", "spi-clk";
			mediatek,pad-select = <0>;
			#address-cells = <1>;
			#size-cells = <0>;
			status = "disabled";
		};

		spi5: spi@11015000 {
			compatible = "mediatek,mt6897-spi", "mediatek,mt6991-spi";
			reg = <0 0x11015000 0 0x100>;
			interrupts = <GIC_SPI 247 IRQ_TYPE_LEVEL_HIGH 0>;
			clocks = <&topckgen CLK_TOP_UNIVPLL_D6_D2>,
				 <&topckgen CLK_TOP_SPI5>,
				 <&pericfg_ao CLK_PERI_AO_SPI5_BCLK>;
			clock-names = "parent-clk", "sel-clk", "spi-clk";
			mediatek,pad-select = <0>;
			#address-cells = <1>;
			#size-cells = <0>;
			status = "disabled";
		};

		spi6: spi@11016000 {
			compatible = "mediatek,mt6897-spi", "mediatek,mt6991-spi";
			reg = <0 0x11016000 0 0x100>;
			interrupts = <GIC_SPI 248 IRQ_TYPE_LEVEL_HIGH 0>;
			clocks = <&topckgen CLK_TOP_UNIVPLL_D6_D2>,
				 <&topckgen CLK_TOP_SPI6>,
				 <&pericfg_ao CLK_PERI_AO_SPI6_BCLK>;
			clock-names = "parent-clk", "sel-clk", "spi-clk";
			mediatek,pad-select = <1>;
			#address-cells = <1>;
			#size-cells = <0>;
			status = "disabled";
		};

		spi7: spi@11017000 {
			compatible = "mediatek,mt6897-spi", "mediatek,mt6991-spi";
			reg = <0 0x11017000 0 0x100>;
			interrupts = <GIC_SPI 249 IRQ_TYPE_LEVEL_HIGH 0>;
			clocks = <&topckgen CLK_TOP_UNIVPLL_D6_D2>,
				 <&topckgen CLK_TOP_SPI7>,
				 <&pericfg_ao CLK_PERI_AO_SPI7_BCLK>;
			clock-names = "parent-clk", "sel-clk", "spi-clk";
			mediatek,pad-select = <1>;
			#address-cells = <1>;
			#size-cells = <0>;
			status = "disabled";
		};

		pericfg_ao: clock-controller@11036000 {
			compatible = "mediatek,mt6897-pericfg-ao", "syscon";
			reg = <0 0x11036000 0 0x1000>;
			mediatek,hardware-voter = <&hwv>;
			#clock-cells = <1>;
			status = "disabled";
		};

		afe: audio-controller@11050000 {
			compatible = "mediatek,mt6897-afe";
			reg = <0 0x11050000 0 0x9000>;
			interrupts = <GIC_SPI 257 IRQ_TYPE_LEVEL_HIGH 0>;
			power-domains = <&scpsys MT6897_POWER_DOMAIN_AUDIO>;
			mediatek,topckgen = <&topckgen>;
			clocks = <&topckgen CLK_TOP_AUD_INTBUS>,
				 <&topckgen CLK_TOP_AUDIO_H>,
				 <&topckgen CLK_TOP_AUD_1>,
				 <&topckgen CLK_TOP_AUD_2>,
				 <&topckgen CLK_TOP_AUD_ENGEN1>,
				 <&topckgen CLK_TOP_AUD_ENGEN2>,
				 <&apmixedsys CLK_APMIXED_APLL1>,
				 <&apmixedsys CLK_APMIXED_APLL2>,
				 <&topckgen CLK_TOP_APLL1_D2>,
				 <&topckgen CLK_TOP_APLL2_D2>,
				 <&topckgen CLK_TOP_APLL1_D4>,
				 <&topckgen CLK_TOP_APLL2_D4>,
				 <&clk26m>;
			clock-names = "top_aud_intbus", "top_aud_h",
				      "top_aud_1", "top_aud_2",
				      "top_aud_eng1", "top_aud_eng2",
				      "apll1", "apll2",
				      "apll1_d2", "apll2_d2",
				      "apll1_d4", "apll2_d4",
				      "clk26m";
			status = "disabled";
		};

		/*
		 * The stock wakeup glue (pericfg_ao 0x200, vendor version 103)
		 * is a different layout from the mainline version 103 (MT8195
		 * IP0), so mediatek,syscon-wakeup and wakeup-source are left out.
		 */
		ssusb: usb@11201000 {
			compatible = "mediatek,mt6897-mtu3", "mediatek,mtu3";
			reg = <0 0x11201000 0 0x2e00>, <0 0x11203e00 0 0x100>;
			reg-names = "mac", "ippc";
			interrupts = <GIC_SPI 160 IRQ_TYPE_LEVEL_HIGH 0>;
			phys = <&u2port0 PHY_TYPE_USB2>, <&u3port0 PHY_TYPE_USB3>;
			/*
			 * MT6897 has no separate ref, mcu or dma clock (the
			 * stock tree gives none); clk26m keeps their places.
			 */
			clocks = <&topckgen CLK_TOP_USB_TOP>, <&clk26m>, <&clk26m>,
				 <&clk26m>, <&topckgen CLK_TOP_SSUSB_XHCI>,
				 <&pericfg_ao CLK_PERI_AO_SSUSB0_FRMCNT>;
			clock-names = "sys_ck", "ref_ck", "mcu_ck", "dma_ck",
				      "xhci_ck", "frmcnt_ck";
			maximum-speed = "super-speed";
			#address-cells = <2>;
			#size-cells = <2>;
			ranges;
			status = "disabled";

			xhci0: usb@11200000 {
				compatible = "mediatek,mt6897-xhci", "mediatek,mtk-xhci";
				reg = <0 0x11200000 0 0x1000>;
				reg-names = "mac";
				interrupts = <GIC_SPI 161 IRQ_TYPE_LEVEL_HIGH 0>;
				clocks = <&clk26m>;
				clock-names = "sys_ck";
				status = "disabled";
			};
		};

		/*
		 * The I2C controllers and their clock gates from here on, in address
		 * order with the other blocks. Like the other clock controllers, the
		 * gates stay off until something uses them. As in the stock tree,
		 * only i2c6 has its pins set by the kernel; the bootloader muxes the
		 * rest, so nothing here changes them.
		 */
		i2c6: i2c@11280000 {
			compatible = "mediatek,mt6897-i2c", "mediatek,mt8188-i2c";
			reg = <0 0x11280000 0 0x1000>, <0 0x11300600 0 0x80>;
			interrupts = <GIC_SPI 192 IRQ_TYPE_LEVEL_HIGH 0>;
			clock-div = <1>;
			clocks = <&imp_iic_wrap_c CLK_IMPC_I2C6>,
				 <&pericfg_ao CLK_PERI_AO_DMA_BCLK>;
			clock-names = "main", "dma";
			#address-cells = <1>;
			#size-cells = <0>;
			status = "disabled";
		};

		imp_iic_wrap_c: clock-controller@11281000 {
			compatible = "mediatek,mt6897-imp-iic-wrap-c", "syscon";
			reg = <0 0x11281000 0 0x1000>;
			#clock-cells = <1>;
			status = "disabled";
		};

		/*
		 * A newer M-PHY revision ("mphy-ver = <1>" in the stock tree)
		 * that takes no clocks and no power sequence from the kernel.
		 * Its reset (ufscfg_ao, MT6897_UFSAO_RST_UFS_MPHY) is left out:
		 * the vendor kernel does not use it either.
		 */
		ufsphy: ufs-phy@112a0000 {
			compatible = "mediatek,mt6897-ufsphy";
			reg = <0 0x112a0000 0 0x10000>;
			#phy-cells = <0>;
			status = "disabled";
		};

		/*
		 * No power domain: the compatible implies the RTFF MTCMOS
		 * power control through the SiP call. The two OPPs are the
		 * vendor's low and high parents of the ufs mux (mainpll_d4_d2,
		 * mmpll_d6) and the aes_ufsfde mux (univpll_d6, mainpll_d4)
		 * behind the main and aes gates; nothing scales them yet.
		 * MCQ also needs the queue interrupts SPI 177-184, which the
		 * UFS binding does not take yet, so start in single doorbell
		 * mode.
		 */
		ufshci: ufshci@112b0000 {
			compatible = "mediatek,mt6897-ufshci";
			reg = <0 0x112b0000 0 0x3000>;
			interrupts = <GIC_SPI 168 IRQ_TYPE_LEVEL_HIGH 0>;
			phys = <&ufsphy>;
			clocks = <&ufscfg_pdn CLK_UFSPDN_UFSHCI_UFS>,
				 <&ufscfg_pdn CLK_UFSPDN_UFSHCI_AES>,
				 <&ufscfg_ao CLK_UFSAO_UNIPRO_SYS>,
				 <&ufscfg_ao CLK_UFSAO_UNIPRO_TX_SYM>,
				 <&ufscfg_ao CLK_UFSAO_UNIPRO_RX_SYM0>,
				 <&ufscfg_ao CLK_UFSAO_UNIPRO_RX_SYM1>;
			clock-names = "main", "aes", "unipro_sysclk", "tx_symbol",
				      "rx_symbol0", "rx_symbol1";
			operating-points-v2 = <&ufs_opp_table>;
			resets = <&ufscfg_pdn MT6897_UFSPDN_RST_UFS_UNIPRO>,
				 <&ufscfg_pdn MT6897_UFSPDN_RST_UFS_CRYPTO>,
				 <&ufscfg_pdn MT6897_UFSPDN_RST_UFSHCI>;
			reset-names = "unipro", "crypto", "hci";
			mediatek,ufs-disable-mcq;
			status = "disabled";

			ufs_opp_table: opp-table {
				compatible = "operating-points-v2";

				opp-273000000 {
					opp-hz = /bits/ 64 <273000000>,
						 /bits/ 64 <416000000>,
						 /bits/ 64 <0>,
						 /bits/ 64 <0>,
						 /bits/ 64 <0>,
						 /bits/ 64 <0>;
				};

				opp-458333313 {
					opp-hz = /bits/ 64 <458333313>,
						 /bits/ 64 <546000000>,
						 /bits/ 64 <0>,
						 /bits/ 64 <0>,
						 /bits/ 64 <0>,
						 /bits/ 64 <0>;
				};
			};
		};

		ufscfg_ao: clock-controller@112b8000 {
			compatible = "mediatek,mt6897-ufscfg-ao", "syscon";
			reg = <0 0x112b8000 0 0x1000>;
			#clock-cells = <1>;
			#reset-cells = <1>;
			status = "disabled";
		};

		ufscfg_pdn: clock-controller@112bb000 {
			compatible = "mediatek,mt6897-ufscfg-pdn", "syscon";
			reg = <0 0x112bb000 0 0x1000>;
			#clock-cells = <1>;
			#reset-cells = <1>;
			status = "disabled";
		};

		i2c2: i2c@11b70000 {
			compatible = "mediatek,mt6897-i2c", "mediatek,mt8188-i2c";
			reg = <0 0x11b70000 0 0x1000>, <0 0x11300300 0 0x100>;
			interrupts = <GIC_SPI 188 IRQ_TYPE_LEVEL_HIGH 0>;
			clock-div = <1>;
			clocks = <&imp_iic_wrap_en CLK_IMPEN_I2C2>,
				 <&pericfg_ao CLK_PERI_AO_DMA_BCLK>;
			clock-names = "main", "dma";
			#address-cells = <1>;
			#size-cells = <0>;
			status = "disabled";
		};

		i2c4: i2c@11b71000 {
			compatible = "mediatek,mt6897-i2c", "mediatek,mt8188-i2c";
			reg = <0 0x11b71000 0 0x1000>, <0 0x11300480 0 0x100>;
			interrupts = <GIC_SPI 190 IRQ_TYPE_LEVEL_HIGH 0>;
			clock-div = <1>;
			clocks = <&imp_iic_wrap_en CLK_IMPEN_I2C4>,
				 <&pericfg_ao CLK_PERI_AO_DMA_BCLK>;
			clock-names = "main", "dma";
			#address-cells = <1>;
			#size-cells = <0>;
			status = "disabled";
		};

		i2c10: i2c@11b72000 {
			compatible = "mediatek,mt6897-i2c", "mediatek,mt8188-i2c";
			reg = <0 0x11b72000 0 0x1000>, <0 0x11300980 0 0x80>;
			interrupts = <GIC_SPI 196 IRQ_TYPE_LEVEL_HIGH 0>;
			clock-div = <1>;
			clocks = <&imp_iic_wrap_en CLK_IMPEN_I2C10>,
				 <&pericfg_ao CLK_PERI_AO_DMA_BCLK>;
			clock-names = "main", "dma";
			#address-cells = <1>;
			#size-cells = <0>;
			status = "disabled";
		};

		i2c11: i2c@11b73000 {
			compatible = "mediatek,mt6897-i2c", "mediatek,mt8188-i2c";
			reg = <0 0x11b73000 0 0x1000>, <0 0x11300a00 0 0x80>;
			interrupts = <GIC_SPI 197 IRQ_TYPE_LEVEL_HIGH 0>;
			clock-div = <1>;
			clocks = <&imp_iic_wrap_en CLK_IMPEN_I2C11>,
				 <&pericfg_ao CLK_PERI_AO_DMA_BCLK>;
			clock-names = "main", "dma";
			#address-cells = <1>;
			#size-cells = <0>;
			status = "disabled";
		};

		imp_iic_wrap_en: clock-controller@11b74000 {
			compatible = "mediatek,mt6897-imp-iic-wrap-en", "syscon";
			reg = <0 0x11b74000 0 0x1000>;
			#clock-cells = <1>;
			status = "disabled";
		};

		i2c8: i2c@11cc0000 {
			compatible = "mediatek,mt6897-i2c", "mediatek,mt8188-i2c";
			reg = <0 0x11cc0000 0 0x1000>, <0 0x11300780 0 0x100>;
			interrupts = <GIC_SPI 194 IRQ_TYPE_LEVEL_HIGH 0>;
			clock-div = <1>;
			clocks = <&imp_iic_wrap_es CLK_IMPES_I2C8>,
				 <&pericfg_ao CLK_PERI_AO_DMA_BCLK>;
			clock-names = "main", "dma";
			#address-cells = <1>;
			#size-cells = <0>;
			status = "disabled";
		};

		i2c9: i2c@11cc1000 {
			compatible = "mediatek,mt6897-i2c", "mediatek,mt8188-i2c";
			reg = <0 0x11cc1000 0 0x1000>, <0 0x11300880 0 0x100>;
			interrupts = <GIC_SPI 195 IRQ_TYPE_LEVEL_HIGH 0>;
			clock-div = <1>;
			clocks = <&imp_iic_wrap_es CLK_IMPES_I2C9>,
				 <&pericfg_ao CLK_PERI_AO_DMA_BCLK>;
			clock-names = "main", "dma";
			#address-cells = <1>;
			#size-cells = <0>;
			status = "disabled";
		};

		i2c12: i2c@11cc2000 {
			compatible = "mediatek,mt6897-i2c", "mediatek,mt8188-i2c";
			reg = <0 0x11cc2000 0 0x1000>, <0 0x11300a80 0 0x80>;
			interrupts = <GIC_SPI 198 IRQ_TYPE_LEVEL_HIGH 0>;
			clock-div = <1>;
			clocks = <&imp_iic_wrap_es CLK_IMPES_I2C12>,
				 <&pericfg_ao CLK_PERI_AO_DMA_BCLK>;
			clock-names = "main", "dma";
			#address-cells = <1>;
			#size-cells = <0>;
			status = "disabled";
		};

		i2c13: i2c@11cc3000 {
			compatible = "mediatek,mt6897-i2c", "mediatek,mt8188-i2c";
			reg = <0 0x11cc3000 0 0x1000>, <0 0x11300b00 0 0x80>;
			interrupts = <GIC_SPI 199 IRQ_TYPE_LEVEL_HIGH 0>;
			clock-div = <1>;
			clocks = <&imp_iic_wrap_es CLK_IMPES_I2C13>,
				 <&pericfg_ao CLK_PERI_AO_DMA_BCLK>;
			clock-names = "main", "dma";
			#address-cells = <1>;
			#size-cells = <0>;
			status = "disabled";
		};

		imp_iic_wrap_es: clock-controller@11cc4000 {
			compatible = "mediatek,mt6897-imp-iic-wrap-es", "syscon";
			reg = <0 0x11cc4000 0 0x1000>;
			#clock-cells = <1>;
			status = "disabled";
		};

		i2c0: i2c@11d00000 {
			compatible = "mediatek,mt6897-i2c", "mediatek,mt8188-i2c";
			reg = <0 0x11d00000 0 0x1000>, <0 0x11300200 0 0x80>;
			interrupts = <GIC_SPI 186 IRQ_TYPE_LEVEL_HIGH 0>;
			clock-div = <1>;
			clocks = <&imp_iic_wrap_s CLK_IMPS_I2C0>,
				 <&pericfg_ao CLK_PERI_AO_DMA_BCLK>;
			clock-names = "main", "dma";
			#address-cells = <1>;
			#size-cells = <0>;
			status = "disabled";
		};

		i2c1: i2c@11d01000 {
			compatible = "mediatek,mt6897-i2c", "mediatek,mt8188-i2c";
			reg = <0 0x11d01000 0 0x1000>, <0 0x11300280 0 0x80>;
			interrupts = <GIC_SPI 187 IRQ_TYPE_LEVEL_HIGH 0>;
			clock-div = <1>;
			clocks = <&imp_iic_wrap_s CLK_IMPS_I2C1>,
				 <&pericfg_ao CLK_PERI_AO_DMA_BCLK>;
			clock-names = "main", "dma";
			#address-cells = <1>;
			#size-cells = <0>;
			status = "disabled";
		};

		i2c7: i2c@11d02000 {
			compatible = "mediatek,mt6897-i2c", "mediatek,mt8188-i2c";
			reg = <0 0x11d02000 0 0x1000>, <0 0x11300680 0 0x100>;
			interrupts = <GIC_SPI 193 IRQ_TYPE_LEVEL_HIGH 0>;
			clock-div = <1>;
			clocks = <&imp_iic_wrap_s CLK_IMPS_I2C7>,
				 <&pericfg_ao CLK_PERI_AO_DMA_BCLK>;
			clock-names = "main", "dma";
			#address-cells = <1>;
			#size-cells = <0>;
			status = "disabled";
		};

		imp_iic_wrap_s: clock-controller@11d03000 {
			compatible = "mediatek,mt6897-imp-iic-wrap-s", "syscon";
			reg = <0 0x11d03000 0 0x1000>;
			#clock-cells = <1>;
			status = "disabled";
		};

		xsphy: xs-phy@11e43000 {
			compatible = "mediatek,mt6897-xsphy", "mediatek,xsphy";
			reg = <0 0x11e43000 0 0x200>;
			#address-cells = <2>;
			#size-cells = <2>;
			ranges;
			status = "disabled";

			/*
			 * The stock eye settings. The stock internal resistor
			 * calibration (0x25, or the efuse value when set) is left
			 * out: on MT6897 it sits in a field that the mainline
			 * driver does not write.
			 */
			u2port0: usb-phy@11e40000 {
				reg = <0 0x11e40000 0 0x400>;
				clocks = <&clk26m>;
				clock-names = "ref";
				mediatek,eye-vrt = <7>;
				mediatek,eye-term = <3>;
				#phy-cells = <1>;
			};

			u3port0: usb-phy@11e43400 {
				reg = <0 0x11e43400 0 0x500>;
				clocks = <&clk26m>;
				clock-names = "ref";
				#phy-cells = <1>;
			};
		};

		mipi_tx0: dsi-phy@11e50000 {
			compatible = "mediatek,mt6897-mipi-tx";
			reg = <0 0x11e50000 0 0x1000>;
			clocks = <&clk26m>;
			clock-output-names = "mipi_tx0_pll";
			#clock-cells = <0>;
			#phy-cells = <0>;
			status = "disabled";
		};

		mipi_tx1: dsi-phy@11e60000 {
			compatible = "mediatek,mt6897-mipi-tx";
			reg = <0 0x11e60000 0 0x1000>;
			clocks = <&clk26m>;
			clock-output-names = "mipi_tx1_pll";
			#clock-cells = <0>;
			#phy-cells = <0>;
			status = "disabled";
		};

		i2c3: i2c@11f00000 {
			compatible = "mediatek,mt6897-i2c", "mediatek,mt8188-i2c";
			reg = <0 0x11f00000 0 0x1000>, <0 0x11300400 0 0x80>;
			interrupts = <GIC_SPI 189 IRQ_TYPE_LEVEL_HIGH 0>;
			clock-div = <1>;
			clocks = <&imp_iic_wrap_n CLK_IMPN_I2C3>,
				 <&pericfg_ao CLK_PERI_AO_DMA_BCLK>;
			clock-names = "main", "dma";
			#address-cells = <1>;
			#size-cells = <0>;
			status = "disabled";
		};

		i2c5: i2c@11f01000 {
			compatible = "mediatek,mt6897-i2c", "mediatek,mt8188-i2c";
			reg = <0 0x11f01000 0 0x1000>, <0 0x11300580 0 0x80>;
			interrupts = <GIC_SPI 191 IRQ_TYPE_LEVEL_HIGH 0>;
			clock-div = <1>;
			clocks = <&imp_iic_wrap_n CLK_IMPN_I2C5>,
				 <&pericfg_ao CLK_PERI_AO_DMA_BCLK>;
			clock-names = "main", "dma";
			#address-cells = <1>;
			#size-cells = <0>;
			status = "disabled";
		};

		imp_iic_wrap_n: clock-controller@11f02000 {
			compatible = "mediatek,mt6897-imp-iic-wrap-n", "syscon";
			reg = <0 0x11f02000 0 0x1000>;
			#clock-cells = <1>;
			status = "disabled";
		};

		/*
		 * The display, MDP and video codec clock gates. These blocks only
		 * answer while their power domain is on, so a consumer powers its
		 * domain before it enables a gate. The nodes have no power-domains:
		 * the VEN and MDP domains need gates of these blocks to come up, and
		 * runtime PM would power a domain up and down at probe, with mm-infra
		 * and the screen. The driver touches neither the blocks nor the
		 * domains at probe.
		 *
		 * The display has a dispsys and an ovlsys for each half of the
		 * screen, and these four do the routing as well. A layer starts in
		 * an ovlsys, crosses to its dispsys and leaves there on a DSI link.
		 * The picture quality blocks and the IOMMU stay out of the path: the
		 * scanout memory has to be contiguous and below 4 GiB.
		 * TODO(2c display): enable with the display pipeline. The interrupts
		 * of disp_mutex1 and ovl_mutex1 follow from the distance of the other
		 * blocks; the driver does not use them.
		 */
		dispsys0: syscon@14000000 {
			compatible = "mediatek,mt6897-dispsys0", "syscon";
			reg = <0 0x14000000 0 0x1000>;
			mediatek,hardware-voter = <&hwv>;
			#clock-cells = <1>;
			status = "disabled";
		};

		disp_mutex0: mutex@14001000 {
			compatible = "mediatek,mt6897-disp-mutex";
			reg = <0 0x14001000 0 0x1000>;
			interrupts = <GIC_SPI 354 IRQ_TYPE_LEVEL_HIGH 0>;
			power-domains = <&scpsys MT6897_POWER_DOMAIN_DIS0_SHUTDOWN>;
			clocks = <&dispsys0 CLK_DISPSYS0_DISP_MUTEX0>,
				 <&dispsys0 CLK_DISPSYS0_DISPSYS_CONFIG>,
				 <&dispsys0 CLK_DISPSYS0_DISP_DLI_ASYNC0>,
				 <&dispsys0 CLK_DISPSYS0_DISP_DLI_ASYNC1>,
				 <&dispsys0 CLK_DISPSYS0_DISP_DLI_ASYNC2>,
				 <&dispsys0 CLK_DISPSYS0_DISP_DLI_ASYNC3>,
				 <&dispsys0 CLK_DISPSYS0_DISP_DLI_ASYNC4>,
				 <&dispsys0 CLK_DISPSYS0_DISP_DLI_ASYNC5>,
				 <&dispsys0 CLK_DISPSYS0_DISP_DLO_ASYNC0>,
				 <&dispsys0 CLK_DISPSYS0_DISP_DLO_ASYNC1>,
				 <&dispsys0 CLK_DISPSYS0_DISP_RELAY0>,
				 <&dispsys0 CLK_DISPSYS0_26M_CLK>,
				 <&dispsys0 CLK_DISPSYS0_SMI_SUB_COMM0>,
				 <&mminfra CLK_MMINFRA_GCE_D>,
				 <&mminfra CLK_MMINFRA_GCE_M>,
				 <&mminfra CLK_MMINFRA_SMI>,
				 <&mminfra CLK_MMINFRA_GCE_26M>;
			status = "disabled";
		};

		dsc0: dsc@1400c000 {
			compatible = "mediatek,mt6897-disp-dsc";
			reg = <0 0x1400c000 0 0x1000>;
			interrupts = <GIC_SPI 366 IRQ_TYPE_LEVEL_HIGH 0>;
			power-domains = <&scpsys MT6897_POWER_DOMAIN_DIS0_SHUTDOWN>;
			clocks = <&dispsys0 CLK_DISPSYS0_DISP_DSC_WRAP0>;
			status = "disabled";
		};

		/* See the board's &dsi0 for the panel */
		dsi0: dsi@1400d000 {
			compatible = "mediatek,mt6897-dsi";
			reg = <0 0x1400d000 0 0x1000>;
			interrupts = <GIC_SPI 368 IRQ_TYPE_LEVEL_HIGH 0>;
			power-domains = <&scpsys MT6897_POWER_DOMAIN_DIS0_SHUTDOWN>;
			clocks = <&dispsys0 CLK_DISPSYS0_DISP_DSI0>,
				 <&dispsys0 CLK_DISPSYS0_DSI_CLK>,
				 <&mipi_tx0>;
			clock-names = "engine", "digital", "hs";
			phys = <&mipi_tx0>;
			phy-names = "dphy";
			#address-cells = <1>;
			#size-cells = <0>;
			status = "disabled";
		};

		dispsys1: syscon@14200000 {
			compatible = "mediatek,mt6897-dispsys1", "syscon";
			reg = <0 0x14200000 0 0x1000>;
			mediatek,hardware-voter = <&hwv>;
			#clock-cells = <1>;
			status = "disabled";
		};

		disp_mutex1: mutex@14201000 {
			compatible = "mediatek,mt6897-disp-mutex";
			reg = <0 0x14201000 0 0x1000>;
			interrupts = <GIC_SPI 398 IRQ_TYPE_LEVEL_HIGH 0>;
			power-domains = <&scpsys MT6897_POWER_DOMAIN_DIS1_SHUTDOWN>;
			clocks = <&dispsys1 CLK_DISPSYS1_DISP_MUTEX0>,
				 <&dispsys1 CLK_DISPSYS1_DISPSYS_CONFIG>,
				 <&dispsys1 CLK_DISPSYS1_DISP_DLI_ASYNC0>,
				 <&dispsys1 CLK_DISPSYS1_DISP_DLI_ASYNC1>,
				 <&dispsys1 CLK_DISPSYS1_DISP_DLI_ASYNC2>,
				 <&dispsys1 CLK_DISPSYS1_DISP_DLI_ASYNC3>,
				 <&dispsys1 CLK_DISPSYS1_DISP_DLI_ASYNC4>,
				 <&dispsys1 CLK_DISPSYS1_DISP_DLI_ASYNC5>,
				 <&dispsys1 CLK_DISPSYS1_DISP_DLO_ASYNC0>,
				 <&dispsys1 CLK_DISPSYS1_DISP_DLO_ASYNC1>,
				 <&dispsys1 CLK_DISPSYS1_DISP_RELAY0>,
				 <&dispsys1 CLK_DISPSYS1_26M_CLK>,
				 <&dispsys1 CLK_DISPSYS1_SMI_SUB_COMM0>;
			status = "disabled";
		};

		dsc1: dsc@1420c000 {
			compatible = "mediatek,mt6897-disp-dsc";
			reg = <0 0x1420c000 0 0x1000>;
			interrupts = <GIC_SPI 367 IRQ_TYPE_LEVEL_HIGH 0>;
			power-domains = <&scpsys MT6897_POWER_DOMAIN_DIS1_SHUTDOWN>;
			clocks = <&dispsys1 CLK_DISPSYS1_DISP_DSC_WRAP0>;
			status = "disabled";
		};

		dsi1: dsi@1420d000 {
			compatible = "mediatek,mt6897-dsi";
			reg = <0 0x1420d000 0 0x1000>;
			interrupts = <GIC_SPI 412 IRQ_TYPE_LEVEL_HIGH 0>;
			power-domains = <&scpsys MT6897_POWER_DOMAIN_DIS1_SHUTDOWN>;
			clocks = <&dispsys1 CLK_DISPSYS1_DISP_DSI0>,
				 <&dispsys1 CLK_DISPSYS1_DSI_CLK>,
				 <&mipi_tx1>;
			clock-names = "engine", "digital", "hs";
			phys = <&mipi_tx1>;
			phy-names = "dphy";
			status = "disabled";
		};

		ovlsys0: syscon@14400000 {
			compatible = "mediatek,mt6897-ovlsys0", "syscon";
			reg = <0 0x14400000 0 0x1000>;
			mediatek,hardware-voter = <&hwv>;
			#clock-cells = <1>;
			status = "disabled";
		};

		ovl_mutex0: mutex@14401000 {
			compatible = "mediatek,mt6897-ovlsys-mutex";
			reg = <0 0x14401000 0 0x1000>;
			interrupts = <GIC_SPI 386 IRQ_TYPE_LEVEL_HIGH 0>;
			power-domains = <&scpsys MT6897_POWER_DOMAIN_OVL0_SHUTDOWN>;
			clocks = <&ovlsys0 CLK_OVLSYS0_DISP_MUTEX0>,
				 <&ovlsys0 CLK_OVLSYS0_CONFIG>,
				 <&ovlsys0 CLK_OVLSYS0_DISP_DLI_ASYNC0>,
				 <&ovlsys0 CLK_OVLSYS0_DISP_DLI_ASYNC1>,
				 <&ovlsys0 CLK_OVLSYS0_DISP_DLI_ASYNC2>,
				 <&ovlsys0 CLK_OVLSYS0_DISP_DLO_ASYNC0>,
				 <&ovlsys0 CLK_OVLSYS0_DISP_DLO_ASYNC1>,
				 <&ovlsys0 CLK_OVLSYS0_DISP_DLO_ASYNC2>,
				 <&ovlsys0 CLK_OVLSYS0_DISP_DLO_ASYNC3>,
				 <&ovlsys0 CLK_OVLSYS0_DISP_DLO_ASYNC4>,
				 <&ovlsys0 CLK_OVLSYS0_DISP_DLO_ASYNC5>,
				 <&ovlsys0 CLK_OVLSYS0_DISP_DLO_ASYNC6>,
				 <&ovlsys0 CLK_OVLSYS0_SMI_SUB_COMMON0>;
			status = "disabled";
		};

		ovl_2l0: ovl@14402000 {
			compatible = "mediatek,mt6897-disp-ovl-2l";
			reg = <0 0x14402000 0 0x1000>;
			interrupts = <GIC_SPI 387 IRQ_TYPE_LEVEL_HIGH 0>;
			power-domains = <&scpsys MT6897_POWER_DOMAIN_OVL0_SHUTDOWN>;
			clocks = <&ovlsys0 CLK_OVLSYS0_OVL0_2L>;
			status = "disabled";
		};

		ovlsys1: syscon@14600000 {
			compatible = "mediatek,mt6897-ovlsys1", "syscon";
			reg = <0 0x14600000 0 0x1000>;
			mediatek,hardware-voter = <&hwv>;
			#clock-cells = <1>;
			status = "disabled";
		};

		ovl_mutex1: mutex@14601000 {
			compatible = "mediatek,mt6897-ovlsys-mutex";
			reg = <0 0x14601000 0 0x1000>;
			interrupts = <GIC_SPI 430 IRQ_TYPE_LEVEL_HIGH 0>;
			power-domains = <&scpsys MT6897_POWER_DOMAIN_OVL1_SHUTDOWN>;
			clocks = <&ovlsys1 CLK_OVLSYS1_DISP_MUTEX0>,
				 <&ovlsys1 CLK_OVLSYS1_CONFIG>,
				 <&ovlsys1 CLK_OVLSYS1_DISP_DLI_ASYNC0>,
				 <&ovlsys1 CLK_OVLSYS1_DISP_DLI_ASYNC1>,
				 <&ovlsys1 CLK_OVLSYS1_DISP_DLI_ASYNC2>,
				 <&ovlsys1 CLK_OVLSYS1_DISP_DLO_ASYNC0>,
				 <&ovlsys1 CLK_OVLSYS1_DISP_DLO_ASYNC1>,
				 <&ovlsys1 CLK_OVLSYS1_DISP_DLO_ASYNC2>,
				 <&ovlsys1 CLK_OVLSYS1_DISP_DLO_ASYNC3>,
				 <&ovlsys1 CLK_OVLSYS1_DISP_DLO_ASYNC4>,
				 <&ovlsys1 CLK_OVLSYS1_DISP_DLO_ASYNC5>,
				 <&ovlsys1 CLK_OVLSYS1_DISP_DLO_ASYNC6>,
				 <&ovlsys1 CLK_OVLSYS1_SMI_SUB_COMMON0>;
			status = "disabled";
		};

		ovl_2l1: ovl@14602000 {
			compatible = "mediatek,mt6897-disp-ovl-2l";
			reg = <0 0x14602000 0 0x1000>;
			interrupts = <GIC_SPI 431 IRQ_TYPE_LEVEL_HIGH 0>;
			power-domains = <&scpsys MT6897_POWER_DOMAIN_OVL1_SHUTDOWN>;
			clocks = <&ovlsys1 CLK_OVLSYS1_OVL0_2L>;
			status = "disabled";
		};

		/*
		 * Video decoder: a front end (LAT) behind larb5 and the display-side
		 * IOMMU, and a core behind larb4 and the MDP IOMMU. The firmware of
		 * the video coprocessor parses the bitstream and drives the
		 * registers. The kernel gives power, clocks, memory and interrupts.
		 * The two IOMMUs share one page table; the child node only makes
		 * the display-side one aware of the front end.
		 */
		vdec: video-codec@16000000 {
			compatible = "mediatek,mt6897-vcodec-dec";
			reg = <0 0x16000000 0 0x1000>,
			      <0 0x1602f000 0 0x1000>,
			      <0 0x16020000 0 0x1000>,
			      <0 0x16021000 0 0x1000>,
			      <0 0x16023000 0 0x1000>,
			      <0 0x16025000 0 0x4000>,
			      <0 0x16010000 0 0x1000>,
			      <0 0x16011000 0 0x400>,
			      <0 0x1600f000 0 0x1000>,
			      <0 0x16004000 0 0x1000>,
			      <0 0x16012000 0 0x1000>,
			      <0 0x16022000 0 0x1000>,
			      <0 0x16015800 0 0x1000>;
			reg-names = "base", "sys", "vld", "mc", "mv", "misc",
				    "lat-misc", "lat-vld", "soc-gcon",
				    "racing-ctrl", "lat-avc-vld", "avc-vld",
				    "av1-vld";
			interrupts = <GIC_SPI 701 IRQ_TYPE_LEVEL_HIGH 0>,
				     <GIC_SPI 704 IRQ_TYPE_LEVEL_HIGH 0>;
			interrupt-names = "core", "lat";
			clocks = <&vdecsys_soc CLK_VDE1_VDEC_CKEN>,
				 <&vdecsys_soc CLK_VDE1_LAT_CKEN>,
				 <&vdecsys CLK_VDE2_VDEC_CKEN>,
				 <&topckgen CLK_TOP_VDEC>;
			clock-names = "soc", "lat", "core", "sel";
			power-domains = <&scpsys MT6897_POWER_DOMAIN_VDE0>,
					<&scpsys MT6897_POWER_DOMAIN_VDE1>;
			power-domain-names = "lat", "core";
			iommus = <&mdp_iommu M4U_PORT_L4_HW_VDEC_MC_EXT>,
				 <&mdp_iommu M4U_PORT_L4_HW_VDEC_UFO_EXT>,
				 <&mdp_iommu M4U_PORT_L4_HW_VDEC_PP_EXT>,
				 <&mdp_iommu M4U_PORT_L4_HW_VDEC_UFO_ENC_EXT>,
				 <&mdp_iommu M4U_PORT_L4_HW_VDEC_PRED_RD_EXT>,
				 <&mdp_iommu M4U_PORT_L4_HW_VDEC_PRED_WR_EXT>,
				 <&mdp_iommu M4U_PORT_L4_HW_VDEC_PPWRAP_EXT>,
				 <&mdp_iommu M4U_PORT_L4_HW_VDEC_TILE_EXT>,
				 <&mdp_iommu M4U_PORT_L4_HW_VDEC_VLD_EXT>,
				 <&mdp_iommu M4U_PORT_L4_HW_VDEC_VLD2_EXT>,
				 <&mdp_iommu M4U_PORT_L4_HW_VDEC_AVC_MV_EXT>;
			mediatek,vcp = <&vcp>;
			status = "disabled";

			lat {
				compatible = "mediatek,mt6897-vcodec-dec-lat";
				iommus = <&disp_iommu M4U_PORT_L5_HW_VDEC_LAT0_VLD_EXT>,
					 <&disp_iommu M4U_PORT_L5_HW_VDEC_LAT0_VLD2_EXT>,
					 <&disp_iommu M4U_PORT_L5_HW_VDEC_LAT0_AVC_MV_EXT>,
					 <&disp_iommu M4U_PORT_L5_HW_VDEC_LAT0_MC_EXT>,
					 <&disp_iommu M4U_PORT_L5_HW_VDEC_LAT0_PRED_RD_EXT>,
					 <&disp_iommu M4U_PORT_L5_HW_VDEC_LAT0_TILE_EXT>,
					 <&disp_iommu M4U_PORT_L5_HW_VDEC_LAT0_WDMA_EXT>,
					 <&disp_iommu M4U_PORT_L5_HW_VDEC_LAT0_UFO_ENC_EXT>,
					 <&disp_iommu M4U_PORT_L5_HW_VDEC_LAT0_UFO_ENC_C_EXT>;
			};
		};

		/*
		 * Video decoder front end. The larb answers only while the VDE0
		 * domain is on; its clocks are the gates of the front end.
		 */
		larb5: larb@1600d000 {
			compatible = "mediatek,mt6897-smi-larb";
			reg = <0 0x1600d000 0 0x1000>;
			mediatek,larb-id = <5>;
			mediatek,smi = <&smi_disp_common>;
			clocks = <&vdecsys_soc CLK_VDE1_VDEC_CKEN>,
				 <&vdecsys_soc CLK_VDE1_LAT_CKEN>;
			clock-names = "apb", "smi";
			power-domains = <&scpsys MT6897_POWER_DOMAIN_VDE0>;
			status = "disabled";
		};

		vdecsys_soc: clock-controller@1600f000 {
			compatible = "mediatek,mt6897-vdecsys-soc", "syscon";
			reg = <0 0x1600f000 0 0x1000>;
			#clock-cells = <1>;
			status = "disabled";
		};

		/*
		 * Video decoder core. The larb answers only while the VDE1
		 * domain is on, and its clock is the gate of the core.
		 */
		larb4: larb@1602e000 {
			compatible = "mediatek,mt6897-smi-larb";
			reg = <0 0x1602e000 0 0x1000>;
			mediatek,larb-id = <4>;
			mediatek,smi = <&smi_mdp_common>;
			clocks = <&vdecsys CLK_VDE2_VDEC_CKEN>,
				 <&vdecsys CLK_VDE2_VDEC_CKEN>;
			clock-names = "apb", "smi";
			power-domains = <&scpsys MT6897_POWER_DOMAIN_VDE1>;
			status = "disabled";
		};

		vdecsys: clock-controller@1602f000 {
			compatible = "mediatek,mt6897-vdecsys", "syscon";
			reg = <0 0x1602f000 0 0x1000>;
			#clock-cells = <1>;
			status = "disabled";
		};

		vencsys: clock-controller@17000000 {
			compatible = "mediatek,mt6897-vencsys", "syscon";
			reg = <0 0x17000000 0 0x1000>;
			#clock-cells = <1>;
			status = "disabled";
		};

		vencsys_c1: clock-controller@17800000 {
			compatible = "mediatek,mt6897-vencsys-c1", "syscon";
			reg = <0 0x17800000 0 0x1000>;
			#clock-cells = <1>;
			status = "disabled";
		};

		/*
		 * Camera clock blocks. They answer only while their power domains
		 * are on, and the CAM_VCORE and CAM_MAIN domains take gates of
		 * them to come up, so they carry no power-domains property.
		 */
		camsys_main: clock-controller@1a000000 {
			compatible = "mediatek,mt6897-camsys-main", "syscon";
			reg = <0 0x1a000000 0 0x1000>;
			#clock-cells = <1>;
			status = "disabled";
		};

		/*
		 * Sensor interface, the CSI-2 receiver. The second region holds
		 * the CSI RX analog front ends, the D-PHY and the CSI-2 MACs.
		 */
		seninf: seninf@1a00e000 {
			compatible = "mediatek,mt6897-seninf";
			reg = <0 0x1a00e000 0 0x18000>, <0 0x11c80000 0 0x30000>;
			reg-names = "base", "ana-rx";
			interrupts = <GIC_SPI 502 IRQ_TYPE_LEVEL_HIGH 0>;
			clocks = <&camsys_main CLK_CAM_MAIN_SENINF>,
				 <&camsys_main CLK_CAM_MAIN_CAM>,
				 <&camsys_main CLK_CAM_MAIN_CAMTG>,
				 <&topckgen CLK_TOP_CAMTM>,
				 <&topckgen CLK_TOP_SENINF>;
			clock-names = "seninf", "cam", "camtg", "camtm", "csi";
			assigned-clocks = <&topckgen CLK_TOP_SENINF>;
			assigned-clock-rates = <312000000>;
			power-domains = <&scpsys MT6897_POWER_DOMAIN_CAM_MAIN>,
					<&scpsys MT6897_POWER_DOMAIN_CSI_RX>;
			power-domain-names = "cam-main", "csi-rx";
			nvmem-cells = <&csi_trim0>;
			nvmem-cell-names = "csi0";
			mediatek,vcp = <&vcp>;
			status = "disabled";

			ports {
				#address-cells = <1>;
				#size-cells = <0>;

				seninf_port0: port@0 {
					reg = <0>;
				};
			};
		};

		cam_vcore: clock-controller@1b204000 {
			compatible = "mediatek,mt6897-cam-vcore", "syscon";
			reg = <0 0x1b204000 0 0x1000>;
			#clock-cells = <1>;
			status = "disabled";
		};

		/*
		 * System Power Manager. A domain joins here with its first
		 * consumer. The driver does not touch a domain at probe and
		 * cannot touch one that is not listed, which keeps the display
		 * domains as the bootloader left them while the screen runs on
		 * simple-framebuffer. Before any consumer under mm-infra joins,
		 * the framebuffer has to hold the display domains with
		 * power-domains: genpd powers mm-infra off with its last user.
		 * TODO(2d): enable with the first consumer.
		 */
		spm: syscon@1c001000 {
			compatible = "mediatek,mt6897-scpsys", "syscon", "simple-mfd";
			reg = <0 0x1c001000 0 0x1000>;
			status = "disabled";

			scpsys: power-controller {
				compatible = "mediatek,mt6897-power-controller";
				access-controllers = <&ifr_bus>, <&vlpcfg_bus>;
				mediatek,hardware-voter = <&hwv>;
				#address-cells = <1>;
				#size-cells = <0>;
				#power-domain-cells = <1>;

				power-domain@MT6897_POWER_DOMAIN_AUDIO {
					reg = <MT6897_POWER_DOMAIN_AUDIO>;
					clocks = <&topckgen CLK_TOP_AUD_INTBUS>,
						 <&pericfg_ao CLK_PERI_AO_AUDIO_SLV_CK>,
						 <&pericfg_ao CLK_PERI_AO_AUDIO_MST_CK>,
						 <&pericfg_ao CLK_PERI_AO_AUDIO_INTBUS_CK>;
					clock-names = "audio", "audio-0", "audio-1", "audio-2";
					#power-domain-cells = <0>;
				};

				power-domain@MT6897_POWER_DOMAIN_CONN {
					reg = <MT6897_POWER_DOMAIN_CONN>;
					#power-domain-cells = <0>;
				};
			};
		};

		/*
		 * Wi-Fi and Bluetooth/GNSS common part. The bootloader looks these
		 * nodes up by their paths, without their unit addresses, and does
		 * not read their status. Only when it finds consys, wifi, gps and
		 * connscp, all of them, does it carve out the firmware memory, load
		 * the firmware and write emi-addr here and memory-region in the
		 * wifi node, so the sizes below are what it reads. gps and connscp
		 * stay out of this tree until the bring-up, which keeps the
		 * bootloader away from all of this before then.
		 * TODO(2d): add them and enable these.
		 */
		wifi: wifi@18000000 {
			compatible = "mediatek,mt6897-wifi";
			reg = <0 0x18000000 0 0x700000>,
			      <0 0x10001000 0 0x1000>;
			interrupts = <GIC_SPI 889 IRQ_TYPE_LEVEL_HIGH 0>;
			mediatek,connsys = <&consys>;
			emi-size = <0x1400000>;
			emi-alignment = <0x1000000>;
			emi-max-addr = <0xc0000000>;
			status = "disabled";
		};

		consys: consys@18001000 {
			compatible = "mediatek,mt6897-consys";
			reg = <0 0x18001000 0 0x1000>,
			      <0 0x11b20000 0 0x1000>;
			reg-names = "cfg-on", "iocfg-rt";
			power-domains = <&scpsys MT6897_POWER_DOMAIN_CONN>;
			emi-addr = /bits/ 64 <0>;
			emi-size = <0xc00000>;
			ro-emi-size = <0x680000>;
			rw-emi-size = <0x480000>;
			ro-bt-emi-size = <0x2e0000>;
			ro-gps-emi-size = <0xa0000>;
			ro-wifi-emi-size = <0x300000>;
			emi-alignment = <0x100000>;
			emi-max-addr = <0x90000000>;
			status = "disabled";
		};

		/*
		 * The Bluetooth radio. The bootloader has no use for this node;
		 * what it loads for it depends on the consys and wifi nodes above.
		 * TODO(2d): enable this after those.
		 */
		bluetooth: bluetooth@18800000 {
			compatible = "mediatek,mt6897-bluetooth";
			reg = <0 0x18800000 0 0x21000>,
			      <0 0x18000000 0 0x80000>;
			reg-names = "bgf", "conn";
			interrupts = <GIC_SPI 614 IRQ_TYPE_LEVEL_HIGH 0>,
				     <GIC_SPI 891 IRQ_TYPE_LEVEL_HIGH 0>;
			interrupt-names = "sw", "bus-hang";
			mediatek,connsys = <&consys>;
			status = "disabled";
		};

		/*
		 * Mali-G615 MC6. Power, clocks and voltages are the GPUEB's. No
		 * dma-coherent: the vendor kernel needs a TF-A call to keep the
		 * DSU up for it, which nothing here makes. No ASN hash either.
		 */
		gpu: gpu@13000000 {
			compatible = "mediatek,mt6897-mali", "arm,mali-valhall-csf";
			reg = <0 0x13000000 0 0x480000>;
			clocks = <&gpueb 0>, <&gpueb 1>;
			clock-names = "core", "stacks";
			interrupts = <GIC_SPI 586 IRQ_TYPE_LEVEL_HIGH 0>,
				     <GIC_SPI 585 IRQ_TYPE_LEVEL_HIGH 0>,
				     <GIC_SPI 584 IRQ_TYPE_LEVEL_HIGH 0>;
			interrupt-names = "job", "mmu", "gpu";
			nvmem-cells = <&gpu_shader_present>;
			nvmem-cell-names = "shader-present";
			power-domains = <&gpueb>;
			#cooling-cells = <2>;
			status = "disabled";
		};

		/*
		 * The name matters: the boot firmware adds the shared memory to the
		 * node at /soc/gpueb. The firmware itself comes from the gpueb
		 * partition, loaded and started by the boot firmware.
		 */
		gpueb: gpueb@13c2fd1c {
			compatible = "mediatek,mt6897-gpufreq";
			reg = <0 0x13c2fd1c 0 0x64>,
			      <0 0x1c001f00 0 0x4>;
			reg-names = "gpr", "mfg0-pwr";
			mboxes = <&gpueb_mbox 0>, <&gpueb_mbox 1>, <&gpueb_mbox 2>,
				 <&gpueb_mbox 3>, <&gpueb_mbox 4>, <&gpueb_mbox 5>,
				 <&gpueb_mbox 7>;
			mbox-names = "fast-dvfs-event", "gpufreq", "sleep", "timer",
				     "fhctl", "ccf", "fast-dvfs";
			#clock-cells = <1>;
			#nvmem-cell-cells = <0>;
			#power-domain-cells = <0>;
			status = "disabled";

			gpu_shader_present: shader-present {
			};
		};

		gpueb_mbox: mailbox@13c2fd80 {
			compatible = "mediatek,mt6897-gpueb-mbox";
			reg = <0 0x13c2fd80 0 0x280>,
			      <0 0x13c62000 0 0x7c>;
			reg-names = "data", "ctl";
			interrupts = <GIC_SPI 588 IRQ_TYPE_LEVEL_HIGH 0>;
			#mbox-cells = <1>;
			status = "disabled";
		};

		lvts_gpu: thermal-sensor@13ff0000 {
			compatible = "mediatek,mt6897-lvts-gpu";
			reg = <0 0x13ff0000 0 0x1000>;
			interrupts = <GIC_SPI 592 IRQ_TYPE_LEVEL_HIGH 0>;
			nvmem-cells = <&lvts_calib1>, <&lvts_calib2>,
				      <&lvts_calib3>, <&lvts_calib4>;
			nvmem-cell-names = "lvts-calib-data-1", "lvts-calib-data-2",
					   "lvts-calib-data-3", "lvts-calib-data-4";
			#thermal-sensor-cells = <1>;
			status = "disabled";
		};

		lvts_apu: thermal-sensor@19004000 {
			compatible = "mediatek,mt6897-lvts-apu";
			reg = <0 0x19004000 0 0x1000>;
			interrupts = <GIC_SPI 635 IRQ_TYPE_LEVEL_HIGH 0>;
			nvmem-cells = <&lvts_calib1>, <&lvts_calib2>,
				      <&lvts_calib3>, <&lvts_calib4>;
			nvmem-cell-names = "lvts-calib-data-1", "lvts-calib-data-2",
					   "lvts-calib-data-3", "lvts-calib-data-4";
			#thermal-sensor-cells = <1>;
			status = "disabled";
		};

		/* TOPRGU, already running when the bootloader hands over */
		watchdog: watchdog@1c00a000 {
			compatible = "mediatek,mt6897-wdt", "mediatek,mt6589-wdt";
			reg = <0 0x1c00a000 0 0x100>;
		};

		/* Bus protection registers, disabled like ifr_bus */
		vlpcfg_bus: syscon@1c00c000 {
			compatible = "mediatek,mt6897-vlpcfg-bus", "syscon";
			reg = <0 0x1c00c000 0 0x1000>;
			status = "disabled";
		};

		keypad: keypad@1c00e000 {
			compatible = "mediatek,mt6897-keypad", "mediatek,mt6779-keypad";
			reg = <0 0x1c00e000 0 0x1000>;
			interrupts = <GIC_SPI 138 IRQ_TYPE_EDGE_RISING 0>;
			clocks = <&clk26m>;
			clock-names = "kpd";
			status = "disabled";
		};

		/*
		 * Collects the requests for core voltage and memory clock. The
		 * stock video firmware asks it for a voltage level before it
		 * decodes a frame. The secure monitor turns it on when the
		 * driver asks; until then voltage and memory clock stay where
		 * the bootloader left them.
		 */
		dvfsrc: system-controller@1c00f000 {
			compatible = "mediatek,mt6897-dvfsrc";
			reg = <0 0x1c00f000 0 0x1000>;
			clocks = <&vlpckgen CLK_VLP_DVFSRC>;
			status = "disabled";
		};

		vlpckgen: clock-controller@1c013000 {
			compatible = "mediatek,mt6897-vlpckgen", "syscon";
			reg = <0 0x1c013000 0 0x1000>;
			#clock-cells = <1>;
			status = "disabled";
		};

		/*
		 * SPMI 2.0 arbiter with two buses, laid out like MT8196. The
		 * vendor register tables match the upstream MT8195 data. All
		 * six PMICs sit on the M bus (the firmware sets no
		 * spmi-dev-mask): MT6363 @4, MT6368 @5, MT6319 @6-8 and
		 * MT6685 @9. The P bus has nothing on it and stays off.
		 * The driver needs an spmiN alias for each bus.
		 * TODO(2b): enable with pio. MT6897 has no PMIF clock gates
		 * (MT8195 has them in infracfg_ao, fed by pwrap_ulposc), so the
		 * PMIF clocks are the VLP pwrap_ulposc mux itself.
		 */
		spmi: spmi-arbiter@1cc00000 {
			compatible = "mediatek,mt6897-spmi", "mediatek,mt8196-spmi";
			ranges = <0 0 0x1cc00000 0x7000>;
			#address-cells = <1>;
			#size-cells = <1>;
			status = "disabled";

			spmi_m: spmi@4000 {
				reg = <0x4000 0x900>, <0x1000 0x100>;
				reg-names = "pmif", "spmimst";
				interrupts-extended = <&pio 248 IRQ_TYPE_LEVEL_HIGH>;
				interrupt-names = "rcs";
				interrupt-controller;
				#interrupt-cells = <3>;
				clocks = <&vlpckgen CLK_VLP_PWRAP_ULPOSC>,
					 <&vlpckgen CLK_VLP_PWRAP_ULPOSC>,
					 <&vlpckgen CLK_VLP_SPMI_M_MST>;
				clock-names = "pmif_sys_ck", "pmif_tmr_ck", "spmimst_clk_mux";
				#address-cells = <2>;
				#size-cells = <0>;
			};

			spmi_p: spmi@6000 {
				reg = <0x6000 0x900>, <0x0 0x100>;
				reg-names = "pmif", "spmimst";
				status = "disabled";
			};
		};

		/*
		 * TODO(2a): the stock kernel does not use the upstream SYST driver,
		 * so enable this broadcast timer only after a first boot works.
		 * Until then the hrtimer broadcast covers deep idle.
		 */
		systimer: timer@1cc10000 {
			compatible = "mediatek,mt6897-timer", "mediatek,mt6765-timer";
			reg = <0 0x1cc10000 0 0x1000>;
			interrupts = <GIC_SPI 330 IRQ_TYPE_LEVEL_HIGH 0>;
			clocks = <&clk13m>;
		};

		mminfra: clock-controller@1e800000 {
			compatible = "mediatek,mt6897-mminfra", "syscon";
			reg = <0 0x1e800000 0 0x1000>;
			mediatek,hardware-voter = <&hwv>;
			#clock-cells = <1>;
			status = "disabled";
		};

		/*
		 * The display-side common and IOMMU. Most of the display runs
		 * through them from the bootloader on, with the MMU bits of its
		 * larb ports cleared. The only master named here is the front
		 * end of the video decoder (larb5), and neither driver writes
		 * anything before it attaches.
		 */
		smi_disp_common: smi@1e801000 {
			compatible = "mediatek,mt6897-smi-common";
			reg = <0 0x1e801000 0 0x1000>;
			clocks = <&mminfra CLK_MMINFRA_GCE_D>,
				 <&mminfra CLK_MMINFRA_GCE_M>,
				 <&mminfra CLK_MMINFRA_SMI>,
				 <&mminfra CLK_MMINFRA_GCE_26M>;
			clock-names = "apb", "smi", "gals0", "gals1";
			power-domains = <&scpsys MT6897_POWER_DOMAIN_MM_INFRA>;
			status = "disabled";
		};

		disp_iommu: iommu@1e802000 {
			compatible = "mediatek,mt6897-iommu-disp";
			reg = <0 0x1e802000 0 0x1000>;
			interrupts = <GIC_SPI 442 IRQ_TYPE_LEVEL_HIGH 0>;
			clocks = <&mminfra CLK_MMINFRA_SMI>;
			clock-names = "bclk";
			power-domains = <&scpsys MT6897_POWER_DOMAIN_MM_INFRA>;
			mediatek,larbs = <&larb5>;
			#iommu-cells = <1>;
			status = "disabled";
		};

		/*
		 * The display runs through this common and this IOMMU from the
		 * bootloader on, with the MMU bits of its larb ports cleared
		 * (larb1, larb20 and larb32 are on this side). Neither driver
		 * writes anything before a master attaches.
		 */
		smi_mdp_common: smi@1e80f000 {
			compatible = "mediatek,mt6897-smi-common";
			reg = <0 0x1e80f000 0 0x1000>;
			clocks = <&mminfra CLK_MMINFRA_GCE_D>,
				 <&mminfra CLK_MMINFRA_GCE_M>,
				 <&mminfra CLK_MMINFRA_SMI>,
				 <&mminfra CLK_MMINFRA_GCE_26M>;
			clock-names = "apb", "smi", "gals0", "gals1";
			power-domains = <&scpsys MT6897_POWER_DOMAIN_MM_INFRA>;
			status = "disabled";
		};

		mdp_iommu: iommu@1e810000 {
			compatible = "mediatek,mt6897-iommu-mdp";
			reg = <0 0x1e810000 0 0x1000>;
			interrupts = <GIC_SPI 447 IRQ_TYPE_LEVEL_HIGH 0>;
			clocks = <&mminfra CLK_MMINFRA_SMI>;
			clock-names = "bclk";
			power-domains = <&scpsys MT6897_POWER_DOMAIN_MM_INFRA>;
			mediatek,larbs = <&larb4>;
			#iommu-cells = <1>;
			status = "disabled";
		};

		/*
		 * Video coprocessor (VCP): a RISC-V core that runs the video
		 * codec firmware. The bootloader loads the firmware and the
		 * secure monitor releases the reset. Its power domain and its
		 * clock are left on by the bootloader. Its memory accesses go
		 * through the MDP IOMMU without an SMI larb.
		 */
		vcp: vcp@1ea00000 {
			compatible = "mediatek,mt6897-vcp";
			reg = <0 0x1ea00000 0 0x40000>,
			      <0 0x1ec24000 0 0x1000>,
			      <0 0x1ec30000 0 0x1000>,
			      <0 0x1ecfb000 0 0x110>,
			      <0 0x1ecfc000 0 0x110>,
			      <0 0x1ecfd000 0 0x110>,
			      <0 0x1ecfe000 0 0x110>,
			      <0 0x1ecff000 0 0x110>;
			reg-names = "sram", "cfg", "core0",
				    "mbox0", "mbox1", "mbox2", "mbox3", "mbox4";
			interrupts = <GIC_SPI 857 IRQ_TYPE_LEVEL_HIGH 0>,
				     <GIC_SPI 859 IRQ_TYPE_LEVEL_HIGH 0>,
				     <GIC_SPI 860 IRQ_TYPE_LEVEL_HIGH 0>,
				     <GIC_SPI 861 IRQ_TYPE_LEVEL_HIGH 0>,
				     <GIC_SPI 862 IRQ_TYPE_LEVEL_HIGH 0>,
				     <GIC_SPI 863 IRQ_TYPE_LEVEL_HIGH 0>;
			interrupt-names = "wdt", "mbox0", "mbox1", "mbox2",
					  "mbox3", "mbox4";
			clocks = <&topckgen CLK_TOP_MMUP>,
				 <&topckgen CLK_TOP_MAINPLL_D3>,
				 <&clk26m>;
			clock-names = "mmup-sel", "mmup-clk", "mmup-26m";
			power-domains = <&scpsys MT6897_POWER_DOMAIN_MM_PROC_DORMANT>;
			iommus = <&mdp_iommu M4U_PORT_L31_VIDEO_UP>;
			status = "disabled";
		};

		mdpsys0: clock-controller@1f000000 {
			compatible = "mediatek,mt6897-mdpsys0", "syscon";
			reg = <0 0x1f000000 0 0x1000>;
			#clock-cells = <1>;
			status = "disabled";
		};

		mdpsys1: clock-controller@1f800000 {
			compatible = "mediatek,mt6897-mdpsys1", "syscon";
			reg = <0 0x1f800000 0 0x1000>;
			#clock-cells = <1>;
			status = "disabled";
		};
	};
};
